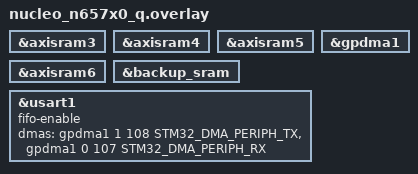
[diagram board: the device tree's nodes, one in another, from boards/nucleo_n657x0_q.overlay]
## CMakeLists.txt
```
# SPDX-License-Identifier: Apache-2.0

cmake_minimum_required(VERSION 3.28.0)

find_package(Zephyr REQUIRED HINTS $ENV{ZEPHYR_BASE})
project(hello_world)

target_sources(app PRIVATE
    src/main.c
    src/blink.c
    src/shell.c
)
```

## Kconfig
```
mainmenu "stm32n6"

source "Kconfig.zephyr"

config APP_HAL_STM32_N6
    bool "ST Cube HAL"
    default y
    select ATOMIC_OPERATIONS_C

    select USE_STM32_HAL_GPIO
    select USE_STM32_HAL_PWR
	select USE_STM32_HAL_PWR_EX
    select USE_STM32_HAL_PKA
	select USE_STM32_HAL_HASH
	select USE_STM32_HAL_CRYP
	select USE_STM32_HAL_CRYP_EX
    select USE_STM32_LL_USB
	select USE_STM32_HAL_PCD
	select USE_STM32_HAL_PCD_EX
```

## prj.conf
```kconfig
# LOG
CONFIG_LOG=y
CONFIG_LOG_MODE_DEFERRED=y

# UART
CONFIG_UART_ASYNC_API=y
CONFIG_NOCACHE_MEMORY=y

# XSPI/MSPI/QSPI
CONFIG_MSPI=y

# SHELL
CONFIG_SHELL=y
CONFIG_SHELL_ASYNC_API=y
CONFIG_SHELL_STACK_SIZE=10240
CONFIG_SHELL_PROMPT_UART="nucleo_n657x0_q: "
CONFIG_SHELL_BACKEND_SERIAL_ASYNC_RX_BUFFER_COUNT=8
CONFIG_SHELL_BACKEND_SERIAL_ASYNC_RX_BUFFER_SIZE=64

# REBOOT
CONFIG_REBOOT=y

# RTC
CONFIG_RTC=y
CONFIG_RTC_SHELL=y

# I2C
CONFIG_I2C=y
CONFIG_I2C_SHELL=y
```

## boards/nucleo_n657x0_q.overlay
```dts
&axisram3 {
    status = "okay";
};

&axisram4 {
    status = "okay";
};

&axisram5 {
    status = "okay";
};

&axisram6 {
    status = "okay";
};

&backup_sram {
    status = "okay";
};

&gpdma1 {
    status = "okay";
};

&usart1 {
	fifo-enable;
	dmas = <&gpdma1 1 108 STM32_DMA_PERIPH_TX>,
	       <&gpdma1 0 107 STM32_DMA_PERIPH_RX>;
	dma-names = "tx", "rx";
};
```

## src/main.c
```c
/*
 * Copyright (c) 2012-2014 Wind River Systems, Inc.
 *
 * SPDX-License-Identifier: Apache-2.0
 */
#include <zephyr/kernel.h>

#include <zephyr/logging/log.h>
LOG_MODULE_REGISTER(main, LOG_LEVEL_INF);

int main(void)
{
	int blink_init(void);

	blink_init();

	LOG_INF("qualifiers: %s", CONFIG_BOARD_QUALIFIERS);
	LOG_INF("board: %s", CONFIG_BOARD);
	LOG_INF("frequency: %d MHz", CONFIG_SYS_CLOCK_HW_CYCLES_PER_SEC/1000000);

	return 0;
}
```

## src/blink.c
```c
#include <stdlib.h>
#include <zephyr/syscalls/time_units.h>
#include <zephyr/kernel.h>
#include <zephyr/drivers/gpio.h>

#include <zephyr/logging/log.h>
LOG_MODULE_REGISTER(blink, LOG_LEVEL_INF);

K_THREAD_STACK_DEFINE(b_thread_stack, 4096);
static struct k_thread b_thread;
static k_tid_t b_thread_id = NULL;

#define LED_DELAY_MS (1000)

static const struct gpio_dt_spec led0 = GPIO_DT_SPEC_GET(DT_ALIAS(led0), gpios);
static const struct gpio_dt_spec led1 = GPIO_DT_SPEC_GET(DT_ALIAS(led1), gpios);
static const struct gpio_dt_spec led2 = GPIO_DT_SPEC_GET(DT_ALIAS(led2), gpios);

static void blink_thread_entry(void *p1, void *p2, void *p3)
{
    uint8_t index = 0;

    ARG_UNUSED(p1);
    ARG_UNUSED(p2);
    ARG_UNUSED(p3);

    while(1)
	{
        switch(index)
        {
            case 0:
                gpio_pin_set_dt(&led0, 0);
                gpio_pin_set_dt(&led1, 1);
                gpio_pin_set_dt(&led2, 0);
                break;
            case 1:
                gpio_pin_set_dt(&led0, 1);
                gpio_pin_set_dt(&led1, 0);
                gpio_pin_set_dt(&led2, 0);
                break;
            case 2:
                gpio_pin_set_dt(&led0, 0);
                gpio_pin_set_dt(&led1, 0);
                gpio_pin_set_dt(&led2, 1);
                break;
            default:
                index = 0;
                break;
        }

        index++;
        if(index > 2)
        {
            index = 0;
        }

		k_sleep(K_MSEC(LED_DELAY_MS));
	}
}

int blink_init(void)
{
    gpio_pin_configure_dt(&led0, GPIO_OUTPUT_INACTIVE);
    gpio_pin_configure_dt(&led1, GPIO_OUTPUT_INACTIVE);
    gpio_pin_configure_dt(&led2, GPIO_OUTPUT_INACTIVE);

	if(b_thread_id != NULL)
	{
		LOG_WRN("thread has been created.");
		return 0;
	}
    b_thread_id = k_thread_create(&b_thread,
										b_thread_stack,
                     					4096,
                     					(k_thread_entry_t)blink_thread_entry,
                     					NULL, NULL, NULL,
                     					K_PRIO_PREEMPT(9), 0, K_NO_WAIT);

	if(b_thread_id != NULL)
  	{
    	k_thread_name_set(b_thread_id, "blink");
  	}
  	else
  	{
		LOG_ERR("blink thread create failed.");
  	}

	return 0;
}
```

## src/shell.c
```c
#include <string.h>
#include <zephyr/init.h>
#include <zephyr/linker/section_tags.h>
#include <zephyr/shell/shell_uart.h>

#if defined(CONFIG_SHELL_BACKEND_SERIAL_API_ASYNC)

BUILD_ASSERT(CONFIG_SHELL_BACKEND_SERIAL_ASYNC_RX_BUFFER_SIZE > 0 &&
	     CONFIG_SHELL_BACKEND_SERIAL_ASYNC_RX_BUFFER_SIZE < BIT(7),
	     "UART async RX helper requires buffer sizes from 1 to 127 bytes");

extern struct shell_transport shell_transport_uart;

/* STM32 DMA requires non-cacheable TX and RX storage. */
static uint8_t shell_dma_tx_buffer[CONFIG_SHELL_PRINTF_BUFF_SIZE] __nocache __aligned(4);
static struct shell_uart_async shell_dma_uart __nocache __aligned(4);
static struct shell_transport_api shell_dma_transport_api;
static const struct shell_transport_api *shell_uart_api;

static int shell_dma_write(const struct shell_transport *transport,
			   const void *data, size_t length, size_t *cnt)
{
	size_t chunk = MIN(length, sizeof(shell_dma_tx_buffer));

	memcpy(shell_dma_tx_buffer, data, chunk);
	return shell_uart_api->write(transport, shell_dma_tx_buffer, chunk, cnt);
}

static int shell_dma_init(void)
{
	memset(shell_dma_tx_buffer, 0, sizeof(shell_dma_tx_buffer));
	memset(&shell_dma_uart, 0, sizeof(shell_dma_uart));
	shell_transport_uart.ctx = &shell_dma_uart;
	shell_uart_api = shell_transport_uart.api;
	shell_dma_transport_api = *shell_uart_api;
	shell_dma_transport_api.write = shell_dma_write;
	shell_transport_uart.api = &shell_dma_transport_api;

	return 0;
}

SYS_INIT(shell_dma_init, PRE_KERNEL_1, 0);

#endif
```
